# MCXN236 register map
Vendor: nxp.com; File version: 1.0
CPU: CM33 r2p0, little endian, MPU, FPU, VTOR, 3 interrupt priority bits
Registers are 32-bit, read-write, reset 0x0 unless marked. A register's access mark holds for its fields unless they carry their own. Offsets are from the block's base; [hi:lo] are bit positions; {n}, {i} and the like mark numbered series.

## USBHS1__USBNC — USBNC
Base 0x4010B200
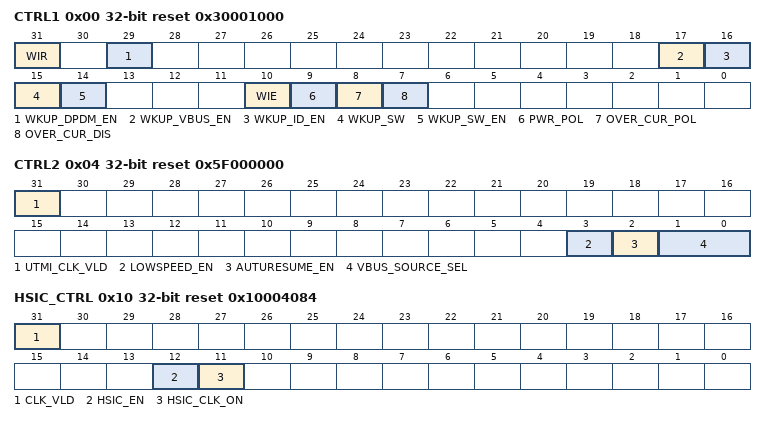
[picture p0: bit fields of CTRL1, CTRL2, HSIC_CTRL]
0x00 CTRL1 reset 0x30001000 — USB OTG Control 1 Register
  [31] WIR ro
    0=NO_WKUP_REQ (No wake-up interrupt request received); 1=WKUP_REQ (Wake-up Interrupt Request received)
  [29] WKUP_DPDM_EN — Wake-up on DPDM change enable
    0=DPDM_WKUP_DIS (DPDM changes wake-up to be disabled only when VBUS is 0.); 1=DPDM_WKUP_EN ((Default) DPDM changes wake-up to be enabled, it is for device only.)
  [17] WKUP_VBUS_EN
    0=WKUP_VBUS_DIS (Disable); 1=WKUP_VBUS_EN (Enable)
  [16] WKUP_ID_EN
    0=WKUP_ID_DIS (Disable); 1=WKUP_ID_EN (Enable)
  [15] WKUP_SW
    0=INACTIVE; 1=FORCE_WKUP (Force wake-up)
  [14] WKUP_SW_EN
    0=SW_WKUP_DIS (Disable); 1=SW_WKUP_EN (Enable)
  [10] WIE
    0=INT_DIS (Interrupt Disabled); 1=INT_EN (Interrupt Enabled)
  [9] PWR_POL
    0=ACTIVE_LO_PMIC (PMIC Power Pin is Low active.); 1=ACTIVE_HI_PMIC (PMIC Power Pin is High active.)
  [8] OVER_CUR_POL
    0=ACTIVE_HI_OVRCRNT (High active (high on this signal represents an overcurrent condition)); 1=ACTIVE_LOW_OVRCRNT (Low active (low on this signal represents an overcurrent condition))
  [7] OVER_CUR_DIS
    0=OVRCRNT_DETCT_EN (Enables overcurrent detection); 1=OVRCRNT_DETCT_DIS (Disables overcurrent detection)
0x04 CTRL2 reset 0x5F000000 — USB OTG Control 2 Register
  [31] UTMI_CLK_VLD write-1-clears
    0=DEFAULT
  [3] LOWSPEED_EN
    0=DEFAULT
  [2] AUTURESUME_EN — Auto Resume Enable
    0=DEFAULT
  [1:0] VBUS_SOURCE_SEL
    0=VBUS_VALID; 1=SESS_VALID_1; 2=SESS_VALID_2; 3=SESS_VALID_3
0x10 HSIC_CTRL reset 0x10004084 — USB Host HSIC Control Register
  [31] CLK_VLD ro
    0=INVALID; 1=VALID
  [12] HSIC_EN
    0=DISABLE (Disabled); 1=ENABLE (Enabled)
  [11] HSIC_CLK_ON
    0=INACTIVE; 1=ACTIVE

## VREF0 — VREF
Base 0x40111000
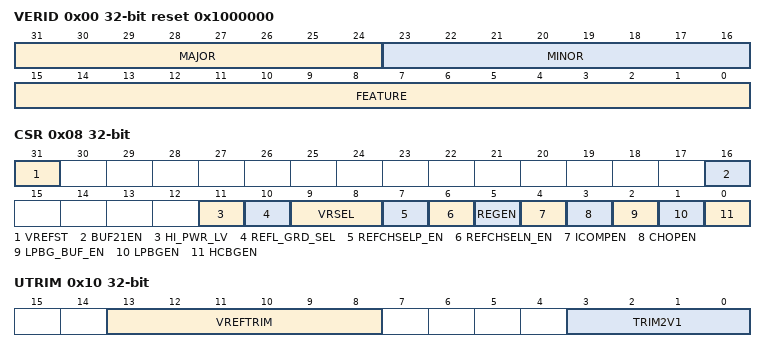
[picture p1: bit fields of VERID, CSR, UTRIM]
0x00 VERID ro reset 0x1000000 — Version ID
  [31:24] MAJOR — Major Version Number
  [23:16] MINOR — Minor Version Number
  [15:0] FEATURE — Feature Specification Number
0x04 PARAM ro — Parameters
0x08 CSR — Control and Status
  [31] VREFST ro — Internal HC Voltage Reference Stable
    0=DIS_NOTSTABLE (Disabled and unstable); 1=STABLE
  [16] BUF21EN — Internal Buffer21 Enable
    0=DIS (Disables); 1=ENA (Enables)
  [11] HI_PWR_LV — High-Power Level
    0=LOW (Low-power); 1=HIGH (High-power)
  [10] REFL_GRD_SEL — Ground Select
    0=VREFL_3V; 1=VSSA
  [9:8] VRSEL — Voltage Reference Selection
    0=BANDGAP (Internal bandgap); 1=ONE_V (Low-power buffered 1v); 2=TWO_PT_ONE_V (Buffer 2.1v output)
  [7] REFCHSELP_EN — Reference Channel Select Positive Enable
    0=DIS (Disables); 1=ENA (Enables)
  [6] REFCHSELN_EN — Reference Channel Select Negative Enable
    0=DIS (Disables); 1=ENA (Enables)
  [5] REGEN — Regulator Enable
    0=DIS (Disables); 1=ENA (Enables)
  [4] ICOMPEN — Current Compensation Enable
    0=DIS (Disables); 1=ENA (Enables)
  [3] CHOPEN — Chop Oscillator Enable
    0=DIS (Disables); 1=ENA (Enables)
  [2] LPBG_BUF_EN — Low-Power Bandgap Buffer Enable
    0=DIS (Disables); 1=ENA (Enables)
  [1] LPBGEN — Low-Power Bandgap Enable
    0=DIS (Disables); 1=ENA (Enables)
  [0] HCBGEN — HC Bandgap Enabled
    0=DIS (Disables); 1=ENA (Enables)
0x10 UTRIM reset not defined — User Trim
  [13:8] VREFTRIM
  [3:0] TRIM2V1 — VREF 2.1V Trim

## SCnSCB — System Control not in System Control Block
Base 0xE000E000
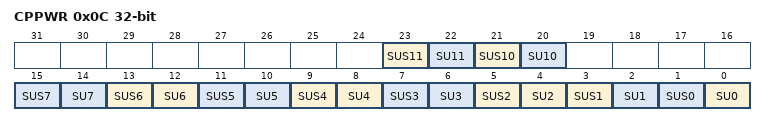
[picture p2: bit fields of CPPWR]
0x0C CPPWR reset not defined — Coprocessor Power Control Register
  [23] SUS11 — State UNKNOWN Secure only 11.
  [22] SU11 — State UNKNOWN 11.
  [21] SUS10 — State UNKNOWN Secure only 10.
    0=SECURE_AND_NON_SECURE (The SU10 field is accessible from both Security states.); 1=SECURE_ONLY (The SU10 field is only accessible from the Secure state.)
  [20] SU10 — State UNKNOWN 10.
    0=UNKNOWN_NOT_PERMITTED (The floating-point state is not permitted to become UNKNOWN.); 1=UNKNOWN_PERMITTED (The floating-point state is permitted to become UNKNOWN)
  [2n+1] SUS{n} (n=2..7) — State UNKNOWN Secure only {n}.
    0=SECURE_AND_NON_SECURE (The SU{n} field is accessible from both Security states.); 1=SECURE_ONLY (The SU{n} field is only accessible from the Secure state.)
  [2n] SU{n} (n=0..7) — State UNKNOWN {n}.
    0=UNKNOWN_NOT_PERMITTED (The coprocessor state is not permitted to become UNKNOWN.); 1=UNKNOWN_PERMITTED (The coprocessor state is permitted to become UNKNOWN.)
  [3] SUS1 — State UNKNOWN Secure only 1.
    0=SECURE_AND_NON_SECURE (The SU7 field is accessible from both Security states.); 1=SECURE_ONLY (The SU7 field is only accessible from the Secure state.)
  [1] SUS0 — State UNKNOWN Secure only 0.
    0=SECURE_AND_NON_SECURE (The SU0 field is accessible from both Security states.); 1=SECURE_ONLY (The SU0 field is only accessible from the Secure state.)
